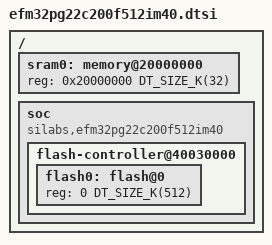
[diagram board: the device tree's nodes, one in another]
/*
 * Copyright (c) 2022 Immanuel Huebner
 *
 * SPDX-License-Identifier: Apache-2.0
 */

#include <mem.h>
#include <silabs/efm32pg22.dtsi>

/ {
	sram0: memory@20000000 {
		reg = <0x20000000 DT_SIZE_K(32)>;
	};

	soc {
		compatible = "silabs,efm32pg22c200f512im40", "silabs,efm32pg22", "silabs,efm32", "simple-bus";

		flash-controller@40030000 {
			flash0: flash@0 {
				reg = <0 DT_SIZE_K(512)>;
			};
		};
	};
};
